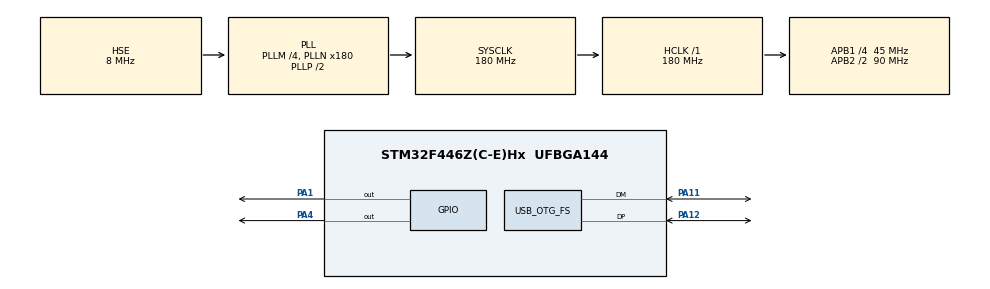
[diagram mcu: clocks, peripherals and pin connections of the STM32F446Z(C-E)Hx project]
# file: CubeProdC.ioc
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Mcu.Family=STM32F4
Mcu.Name=STM32F446Z(C-E)Hx
Mcu.Package=UFBGA144
NVIC.OTG_FS_IRQn=true\:0\:0\:false\:false\:true\:false\:true
NVIC.PriorityGroup=NVIC_PRIORITYGROUP_4
PA1.PinState=GPIO_PIN_SET
PA1.Signal=GPIO_Output
PA11.Mode=Device_Only
PA11.Signal=USB_OTG_FS_DM
PA12.Mode=Device_Only
PA12.Signal=USB_OTG_FS_DP
PA13.Mode=Serial_Wire
PA13.Signal=SYS_JTMS-SWDIO
PA14.Mode=Serial_Wire
PA14.Signal=SYS_JTCK-SWCLK
PA4.PinState=GPIO_PIN_SET
PA4.Signal=GPIO_Output
PH0-OSC_IN.Mode=HSE-External-Oscillator
PH0-OSC_IN.Signal=RCC_OSC_IN
PH1-OSC_OUT.Mode=HSE-External-Oscillator
PH1-OSC_OUT.Signal=RCC_OSC_OUT
ProjectManager.HeapSize=0x200
ProjectManager.StackSize=0x400
ProjectManager.TargetToolchain=STM32CubeIDE
RCC.AHBFreq_Value=180000000
RCC.APB1CLKDivider=RCC_HCLK_DIV4
RCC.APB1Freq_Value=45000000
RCC.APB1TimFreq_Value=90000000
RCC.APB2CLKDivider=RCC_HCLK_DIV2
RCC.APB2Freq_Value=90000000
RCC.APB2TimFreq_Value=180000000
RCC.CortexFreq_Value=180000000
RCC.HCLKFreq_Value=180000000
RCC.HSE_VALUE=8000000
RCC.PLLM=4
RCC.PLLN=180
RCC.PLLQ=3
RCC.PLLSAIM=8
RCC.PLLSAIP=RCC_PLLSAIP_DIV4
RCC.PLLSourceVirtual=RCC_PLLSOURCE_HSE
RCC.SYSCLKFreq_VALUE=180000000
RCC.SYSCLKSource=RCC_SYSCLKSOURCE_PLLCLK
RCC.USBCLockSelection=RCC_CLK48CLKSOURCE_PLLSAIP
RCC.USBFreq_Value=48000000
RCC.VCOOutputFreq_Value=360000000
USB_DEVICE.CLASS_NAME_FS=CDC
USB_DEVICE.VirtualMode-CDC_FS=Cdc
USB_DEVICE.VirtualModeFS=Cdc_FS
USB_OTG_FS.VirtualMode=Device_Only
VP_TIM1_VS_ClockSourceINT.Mode=Internal
VP_USB_DEVICE_VS_USB_DEVICE_CDC_FS.Mode=CDC_FS
board=custom

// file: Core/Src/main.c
/* USER CODE BEGIN Header */
/**
  ******************************************************************************
  * @file           : main.c
  * @brief          : Main program body
  ******************************************************************************
  * @attention
  *
  * <h2><center>&copy; Copyright (c) 2023 STMicroelectronics.
  * All rights reserved.</center></h2>
  *
  * This software component is licensed by ST under BSD 3-Clause license,
  * the "License"; You may not use this file except in compliance with the
  * License. You may obtain a copy of the License at:
  *                        opensource.org/licenses/BSD-3-Clause
  *
  ******************************************************************************
  */
/* USER CODE END Header */
#include "main.h"
#include "usb_device.h"

/* USER CODE BEGIN Includes */
#include "pins.h"
#include "usbd_cdc_if.h"
#include "LED_cube.h"
//#include "ARGB.h"
/* USER CODE END Includes */

TIM_HandleTypeDef htim1;

void SystemClock_Config(void);
static void MX_GPIO_Init(void);
static void MX_TIM1_Init(void);

/* USER CODE BEGIN 0 */
uint8_t cube_colors[CUBE_MASSIVE_SIZE];
uint32_t led_index = 0;
/* USER CODE END 0 */

int main(void)
{

  /* MCU Configuration--------------------------------------------------------*/

  /* Reset of all peripherals, Initializes the Flash interface and the Systick. */
  HAL_Init();

  /* Configure the system clock */
  SystemClock_Config();

  /* Initialize all configured peripherals */
  MX_GPIO_Init();
  MX_USB_DEVICE_Init();
  MX_TIM1_Init();
  /* USER CODE BEGIN 2 */
  HAL_TIM_Base_Start(&htim1);

  cube_set_zero(cube_colors);
  stdin_set_params();
  /* USER CODE END 2 */

  /* Infinite loop */
  /* USER CODE BEGIN WHILE */
  get_cube(cube_colors);
  while(1) {
	  send_cube(cube_colors);
    /* USER CODE END WHILE */

  }
}

void SystemClock_Config(void)
{
  RCC_OscInitTypeDef RCC_OscInitStruct = {0};
  RCC_ClkInitTypeDef RCC_ClkInitStruct = {0};

  /** Configure the main internal regulator output voltage
  */
  __HAL_RCC_PWR_CLK_ENABLE();
  __HAL_PWR_VOLTAGESCALING_CONFIG(PWR_REGULATOR_VOLTAGE_SCALE1);
  /** Initializes the RCC Oscillators according to the specified parameters
  * in the RCC_OscInitTypeDef structure.
  */
  RCC_OscInitStruct.OscillatorType = RCC_OSCILLATORTYPE_HSE;
  RCC_OscInitStruct.HSEState = RCC_HSE_ON;
  RCC_OscInitStruct.PLL.PLLState = RCC_PLL_ON;
  RCC_OscInitStruct.PLL.PLLSource = RCC_PLLSOURCE_HSE;
  RCC_OscInitStruct.PLL.PLLM = 4;
  RCC_OscInitStruct.PLL.PLLN = 180;
  RCC_OscInitStruct.PLL.PLLP = RCC_PLLP_DIV2;
  RCC_OscInitStruct.PLL.PLLQ = 3;
  RCC_OscInitStruct.PLL.PLLR = 2;
  if (HAL_RCC_OscConfig(&RCC_OscInitStruct) != HAL_OK)
  {
    Error_Handler();
  }
  /** Activate the Over-Drive mode
  */
  if (HAL_PWREx_EnableOverDrive() != HAL_OK)
  {
    Error_Handler();
  }
  /** Initializes the CPU, AHB and APB buses clocks
  */
  RCC_ClkInitStruct.ClockType = RCC_CLOCKTYPE_HCLK|RCC_CLOCKTYPE_SYSCLK
                              |RCC_CLOCKTYPE_PCLK1|RCC_CLOCKTYPE_PCLK2;
  RCC_ClkInitStruct.SYSCLKSource = RCC_SYSCLKSOURCE_PLLCLK;
  RCC_ClkInitStruct.AHBCLKDivider = RCC_SYSCLK_DIV1;
  RCC_ClkInitStruct.APB1CLKDivider = RCC_HCLK_DIV4;
  RCC_ClkInitStruct.APB2CLKDivider = RCC_HCLK_DIV2;

  if (HAL_RCC_ClockConfig(&RCC_ClkInitStruct, FLASH_LATENCY_5) != HAL_OK)
  {
    Error_Handler();
  }
}

static void MX_TIM1_Init(void)
{

  TIM_ClockConfigTypeDef sClockSourceConfig = {0};
  TIM_MasterConfigTypeDef sMasterConfig = {0};

  htim1.Instance = TIM1;
  htim1.Init.Prescaler = 0;
  htim1.Init.CounterMode = TIM_COUNTERMODE_UP;
  htim1.Init.Period = 65535;
  htim1.Init.ClockDivision = TIM_CLOCKDIVISION_DIV1;
  htim1.Init.RepetitionCounter = 0;
  htim1.Init.AutoReloadPreload = TIM_AUTORELOAD_PRELOAD_DISABLE;
  if (HAL_TIM_Base_Init(&htim1) != HAL_OK)
  {
    Error_Handler();
  }
  sClockSourceConfig.ClockSource = TIM_CLOCKSOURCE_INTERNAL;
  if (HAL_TIM_ConfigClockSource(&htim1, &sClockSourceConfig) != HAL_OK)
  {
    Error_Handler();
  }
  sMasterConfig.MasterOutputTrigger = TIM_TRGO_RESET;
  sMasterConfig.MasterSlaveMode = TIM_MASTERSLAVEMODE_DISABLE;
  if (HAL_TIMEx_MasterConfigSynchronization(&htim1, &sMasterConfig) != HAL_OK)
  {
    Error_Handler();
  }

}

static void MX_GPIO_Init(void)
{
  GPIO_InitTypeDef GPIO_InitStruct = {0};

  /* GPIO Ports Clock Enable */
  __HAL_RCC_GPIOA_CLK_ENABLE();
  __HAL_RCC_GPIOH_CLK_ENABLE();

  /*Configure GPIO pin Output Level */
  HAL_GPIO_WritePin(GPIOA, GPIO_PIN_4|GPIO_PIN_1, GPIO_PIN_SET);

  /*Configure GPIO pins : PA4 PA1 */
  GPIO_InitStruct.Pin = GPIO_PIN_4|GPIO_PIN_1;
  GPIO_InitStruct.Mode = GPIO_MODE_OUTPUT_PP;
  GPIO_InitStruct.Pull = GPIO_NOPULL;
  GPIO_InitStruct.Speed = GPIO_SPEED_FREQ_LOW;
  HAL_GPIO_Init(GPIOA, &GPIO_InitStruct);

}

/* USER CODE BEGIN 4 */
void SetColor(_pin pin, uint8_t r, uint8_t g, uint8_t b) {
/*	uint32_t pwm[24];
	uint32_t color = (g << 16) | (r << 8) | b;
	for (int i = 23; i >= 0; --i) {
		if (color & (1 << i))
			pwm[i] = 60;
		else
			pwm[i] = 30;
	}

	HAL_TIM_PWM_Start_DMA(&htim1, TIM_CHANNEL_1, (uint32_t *)pwm, 24);*/
}

/*void HAL_TIM_PWM_PulseFinishedCallback(TIM_HandleTypeDef *htim) {
	HAL_TIM_PWM_Stop_DMA(&htim1, TIM_CHANNEL_1);
}*/
/* USER CODE END 4 */

void Error_Handler(void)
{
  __disable_irq();
  while (1)
  {
  }
}

/************************ (C) COPYRIGHT STMicroelectronics *****END OF FILE****/
